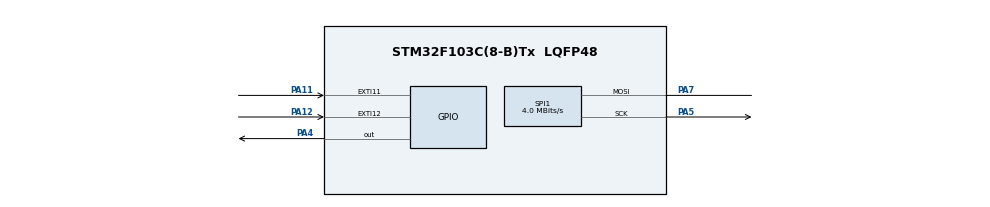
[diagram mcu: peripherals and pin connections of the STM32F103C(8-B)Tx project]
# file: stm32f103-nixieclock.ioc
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Mcu.Family=STM32F1
Mcu.Name=STM32F103C(8-B)Tx
Mcu.Package=LQFP48
NVIC.EXTI15_10_IRQn=true\:0\:0\:false\:false\:true\:true\:true
NVIC.PriorityGroup=NVIC_PRIORITYGROUP_4
PA11.Signal=GPXTI11
PA12.Signal=GPXTI12
PA13.Mode=Serial_Wire
PA13.Signal=SYS_JTMS-SWDIO
PA14.Mode=Serial_Wire
PA14.Signal=SYS_JTCK-SWCLK
PA4.Signal=GPIO_Output
PA5.Mode=Simplex_Bidirectional_Master
PA5.Signal=SPI1_SCK
PA7.Mode=Simplex_Bidirectional_Master
PA7.Signal=SPI1_MOSI
PC14-OSC32_IN.Mode=LSE-External-Oscillator
PC14-OSC32_IN.Signal=RCC_OSC32_IN
PC15-OSC32_OUT.Mode=LSE-External-Oscillator
PC15-OSC32_OUT.Signal=RCC_OSC32_OUT
ProjectManager.HeapSize=0x200
ProjectManager.StackSize=0x400
ProjectManager.TargetToolchain=Makefile
RCC.APB1Freq_Value=8000000
RCC.APB2Freq_Value=8000000
RCC.RTCClockSelection=RCC_RTCCLKSOURCE_LSE
RTC.Date=17
RTC.Format=RTC_FORMAT_BIN
RTC.Hours=19
RTC.Minutes=27
RTC.Month=RTC_MONTH_JULY
RTC.Seconds=35
RTC.WeekDay=RTC_WEEKDAY_FRIDAY
RTC.Year=20
SPI1.CalculateBaudRate=4.0 MBits/s
SPI1.Direction=SPI_DIRECTION_1LINE
SPI1.Mode=SPI_MODE_MASTER
SPI1.VirtualType=VM_MASTER
VP_RTC_VS_RTC_Activate.Mode=RTC_Enabled
VP_RTC_VS_RTC_Calendar.Mode=RTC_Calendar
board=custom

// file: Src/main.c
/* USER CODE BEGIN Header */
/**
  ******************************************************************************
  * @file           : main.c
  * @brief          : Main program body
  ******************************************************************************
  * @attention
  *
  * <h2><center>&copy; Copyright (c) 2020 STMicroelectronics.
  * All rights reserved.</center></h2>
  *
  * This software component is licensed by ST under BSD 3-Clause license,
  * the "License"; You may not use this file except in compliance with the
  * License. You may obtain a copy of the License at:
  *                        opensource.org/licenses/BSD-3-Clause
  *
  ******************************************************************************
  */
/* USER CODE END Header */

#include "main.h"

/* USER CODE BEGIN Includes */
#include "nixie.h"
/* USER CODE END Includes */

RTC_HandleTypeDef hrtc;

SPI_HandleTypeDef hspi1;

uint8_t temp = 0;

void SystemClock_Config(void);
static void MX_GPIO_Init(void);
static void MX_RTC_Init(void);
static void MX_SPI1_Init(void);

int main(void)
{

  /* MCU Configuration--------------------------------------------------------*/

  /* Reset of all peripherals, Initializes the Flash interface and the Systick. */
  HAL_Init();

  /* Configure the system clock */
  SystemClock_Config();

  /* Initialize all configured peripherals */
  MX_GPIO_Init();
  MX_RTC_Init();
  MX_SPI1_Init();
  /* USER CODE BEGIN 2 */
  // RTC_TimeTypeDef gTime;
  // uint8_t seconds;
  // uint8_t tens_seconds;
  // uint8_t minutes;
  // uint8_t tens_minutes;
  // uint8_t hour;
  // uint8_t tens_hour;

  // RTC_DateTypeDef gDate;
  // uint8_t day;
  // uint8_t tens_day;
  // uint8_t month;
  // uint8_t tens_month;
  // uint8_t year;
  // uint8_t tens_year;
  /* USER CODE END 2 */

  /* Infinite loop */
  /* USER CODE BEGIN WHILE */
  while (1)
  {
    Display_AlphaWorldlines();
    // HAL_RTC_GetTime(&hrtc, &gTime, RTC_FORMAT_BIN);
    // seconds  = gTime.Seconds % 10;
    // tens_seconds = gTime.Seconds / 10;
    // minutes  = gTime.Minutes % 10;
    // tens_minutes = gTime.Minutes / 10;
    // hour  = gTime.Hours % 10;
    // tens_hour = gTime.Hours / 10;

    // HAL_RTC_GetDate(&hrtc, &gDate, RTC_FORMAT_BIN);
    // day  = gDate.Date % 10;
    // tens_day = gDate.Date / 10;
    // month  = gDate.Month % 10;
    // tens_month = gDate.Month / 10;
    // year  = gDate.Year % 10;
    // tens_year = gDate.Year / 10;

    // if (temp == 0){
    //   Nixie8(seconds);
    //   Nixie7(tens_seconds);
    //   Nixie5(minutes);
    //   Nixie4(tens_minutes);
    //   Nixie2(hour);
    //   Nixie1(tens_hour);
    //   HAL_Delay(1);
    // }

    // if (temp == 1){
    //   Nixie8(day);
    //   Nixie7(tens_day);
    //   Nixie5(month);
    //   Nixie4(tens_month);
    //   Nixie2(year);
    //   Nixie1(tens_year);
    //   HAL_Delay(1);
    // }
    /* USER CODE END WHILE */

  }
}

void SystemClock_Config(void)
{
  RCC_OscInitTypeDef RCC_OscInitStruct = {0};
  RCC_ClkInitTypeDef RCC_ClkInitStruct = {0};
  RCC_PeriphCLKInitTypeDef PeriphClkInit = {0};

  /** Initializes the CPU, AHB and APB busses clocks
  */
  RCC_OscInitStruct.OscillatorType = RCC_OSCILLATORTYPE_HSI|RCC_OSCILLATORTYPE_LSE;
  RCC_OscInitStruct.LSEState = RCC_LSE_ON;
  RCC_OscInitStruct.HSIState = RCC_HSI_ON;
  RCC_OscInitStruct.HSICalibrationValue = RCC_HSICALIBRATION_DEFAULT;
  RCC_OscInitStruct.PLL.PLLState = RCC_PLL_NONE;
  if (HAL_RCC_OscConfig(&RCC_OscInitStruct) != HAL_OK)
  {
    Error_Handler();
  }
  /** Initializes the CPU, AHB and APB busses clocks
  */
  RCC_ClkInitStruct.ClockType = RCC_CLOCKTYPE_HCLK|RCC_CLOCKTYPE_SYSCLK
                              |RCC_CLOCKTYPE_PCLK1|RCC_CLOCKTYPE_PCLK2;
  RCC_ClkInitStruct.SYSCLKSource = RCC_SYSCLKSOURCE_HSI;
  RCC_ClkInitStruct.AHBCLKDivider = RCC_SYSCLK_DIV1;
  RCC_ClkInitStruct.APB1CLKDivider = RCC_HCLK_DIV1;
  RCC_ClkInitStruct.APB2CLKDivider = RCC_HCLK_DIV1;

  if (HAL_RCC_ClockConfig(&RCC_ClkInitStruct, FLASH_LATENCY_0) != HAL_OK)
  {
    Error_Handler();
  }
  PeriphClkInit.PeriphClockSelection = RCC_PERIPHCLK_RTC;
  PeriphClkInit.RTCClockSelection = RCC_RTCCLKSOURCE_LSE;
  if (HAL_RCCEx_PeriphCLKConfig(&PeriphClkInit) != HAL_OK)
  {
    Error_Handler();
  }
}

static void MX_RTC_Init(void)
{

  RTC_TimeTypeDef sTime = {0};
  RTC_DateTypeDef DateToUpdate = {0};

  /** Initialize RTC Only
  */
  hrtc.Instance = RTC;
  hrtc.Init.AsynchPrediv = RTC_AUTO_1_SECOND;
  hrtc.Init.OutPut = RTC_OUTPUTSOURCE_ALARM;
  if (HAL_RTC_Init(&hrtc) != HAL_OK)
  {
    Error_Handler();
  }

  /** Initialize RTC and set the Time and Date
  */
  sTime.Hours = 20;
  sTime.Minutes = 0;
  sTime.Seconds = 0;

  if (HAL_RTC_SetTime(&hrtc, &sTime, RTC_FORMAT_BIN) != HAL_OK)
  {
    Error_Handler();
  }
  DateToUpdate.WeekDay = RTC_WEEKDAY_FRIDAY;
  DateToUpdate.Month = RTC_MONTH_JULY;
  DateToUpdate.Date = 17;
  DateToUpdate.Year = 20;

  if (HAL_RTC_SetDate(&hrtc, &DateToUpdate, RTC_FORMAT_BIN) != HAL_OK)
  {
    Error_Handler();
  }

}

static void MX_SPI1_Init(void)
{

  /* SPI1 parameter configuration*/
  hspi1.Instance = SPI1;
  hspi1.Init.Mode = SPI_MODE_MASTER;
  hspi1.Init.Direction = SPI_DIRECTION_1LINE;
  hspi1.Init.DataSize = SPI_DATASIZE_8BIT;
  hspi1.Init.CLKPolarity = SPI_POLARITY_LOW;
  hspi1.Init.CLKPhase = SPI_PHASE_1EDGE;
  hspi1.Init.NSS = SPI_NSS_SOFT;
  hspi1.Init.BaudRatePrescaler = SPI_BAUDRATEPRESCALER_2;
  hspi1.Init.FirstBit = SPI_FIRSTBIT_MSB;
  hspi1.Init.TIMode = SPI_TIMODE_DISABLE;
  hspi1.Init.CRCCalculation = SPI_CRCCALCULATION_DISABLE;
  hspi1.Init.CRCPolynomial = 10;
  if (HAL_SPI_Init(&hspi1) != HAL_OK)
  {
    Error_Handler();
  }

}

static void MX_GPIO_Init(void)
{
  GPIO_InitTypeDef GPIO_InitStruct = {0};

  /* GPIO Ports Clock Enable */
  __HAL_RCC_GPIOC_CLK_ENABLE();
  __HAL_RCC_GPIOA_CLK_ENABLE();

  /*Configure GPIO pin Output Level */
  HAL_GPIO_WritePin(GPIOA, GPIO_PIN_4, GPIO_PIN_RESET);

  /*Configure GPIO pin : PA4 */
  GPIO_InitStruct.Pin = GPIO_PIN_4;
  GPIO_InitStruct.Mode = GPIO_MODE_OUTPUT_PP;
  GPIO_InitStruct.Pull = GPIO_NOPULL;
  GPIO_InitStruct.Speed = GPIO_SPEED_FREQ_LOW;
  HAL_GPIO_Init(GPIOA, &GPIO_InitStruct);

  /*Configure GPIO pins : PA11 PA12 */
  GPIO_InitStruct.Pin = GPIO_PIN_11|GPIO_PIN_12;
  GPIO_InitStruct.Mode = GPIO_MODE_IT_RISING;
  GPIO_InitStruct.Pull = GPIO_NOPULL;
  HAL_GPIO_Init(GPIOA, &GPIO_InitStruct);

  /* EXTI interrupt init*/
  HAL_NVIC_SetPriority(EXTI15_10_IRQn, 0, 0);
  HAL_NVIC_EnableIRQ(EXTI15_10_IRQn);

}

void Error_Handler(void)
{
}

/************************ (C) COPYRIGHT STMicroelectronics *****END OF FILE****/
